AUTOSAR XML (schema 4-3-0)
package /ComponentTypes
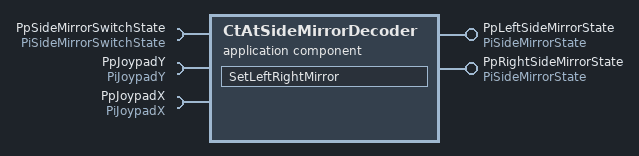
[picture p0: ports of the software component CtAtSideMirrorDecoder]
  application sw component type CtAtSideMirrorDecoder
    require port PpSideMirrorSwitchState: nonqueued-receiver-com-spec{data-element=DeSideMirrorSelectionState, filter=data-filter-type=ALWAYS, init-value=0}, required-interface=PiSideMirrorSwitchState
    require port PpJoypadY: nonqueued-receiver-com-spec{data-element=DeJoypadY, init-value=0}, required-interface=PiJoypadY
    require port PpJoypadX: nonqueued-receiver-com-spec{data-element=DeJoypadX, filter=data-filter-type=ALWAYS, init-value=0}, required-interface=PiJoypadX
    provide port PpLeftSideMirrorState: nonqueued-sender-com-spec{data-element=DeSidMirrorState, init-value=0}, provided-interface=PiSideMirrorState
    provide port PpRightSideMirrorState: nonqueued-sender-com-spec=DeSidMirrorState, provided-interface=PiSideMirrorState
    behavior CtAtSideMirrorDecoder_InternalBehavior
      data received event DRT_SetLeftRightMirror_PpSideMirrorSwitchState_DeSideMirrorSelectionState: start-on-event=SetLeftRightMirror, data=PpSideMirrorSwitchState.DeSideMirrorSelectionState
      runnable SetLeftRightMirror  # Left Value = 1 Right Value = 2
        data-receive-point-by-arguments:
          access REC_PpJoypadX_DeJoypadX: accessed-variable=PpJoypadX.DeJoypadX
          access REC_PpJoypadY_DeJoypadY: accessed-variable=PpJoypadY.DeJoypadY
          access REC_PpSideMirrorSwitchState_DeSideMirrorSelectionState: accessed-variable=PpSideMirrorSwitchState.DeSideMirrorSelectionState
        data-send-points:
          access SEND_PpLeftSideMirrorState_DeSidMirrorState: accessed-variable=PpLeftSideMirrorState.DeSidMirrorState
          access SEND_PpRightSideMirrorState_DeSidMirrorState: accessed-variable=PpRightSideMirrorState.DeSidMirrorState
  swc implementation CtAtSideMirrorDecoder_Implementation: behavior=CtAtSideMirrorDecoder_InternalBehavior
